# CY8C5568AXI_060 register map
File version: 0.1
Registers are 8-bit, read-write, no defined reset value unless marked. A register's access mark holds for its fields unless they carry their own. Offsets are from the block's base; [hi:lo] are bit positions; {n}, {i} and the like mark numbered series; 'fields as' and 'values as' point back to an identical list.

## IDAC8_PulseIR
Base 0x400043A8
0x00 IDAC8_PM_ACT_CFG — Active Power Mode Configuration Register 8
  [3:0] en_dac — Enable DAC block(s). Populated subsystems are counted from the LSB.
0x10 IDAC8_PM_STBY_CFG — Standby Power Mode Configuration Register 8
  fields as IDAC8_PM_ACT_CFG
0x262 IDAC8_TR
  [7:0] tr — 8 Calibration bits
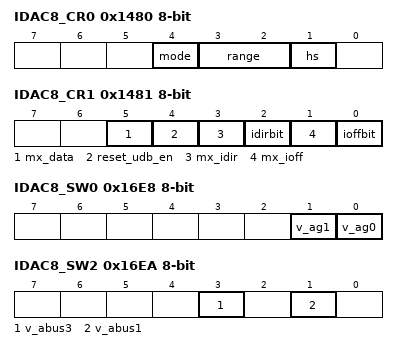
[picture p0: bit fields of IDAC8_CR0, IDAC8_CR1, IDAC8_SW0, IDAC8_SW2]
0x1480 IDAC8_CR0 — DAC Block Control Register 0
  [4] mode ro — Mode Bit
    0=DAC_MODE_V (voltage DAC); 1=DAC_MODE_I (current DAC)
  [3:2] range — Ranges for mode=0 (VDAC) and mode=1 (IDAC)
    0=DAC_RANGE_0 (x0=0V to 4*vref (1.024V); 0 to 31.875uA); 1=DAC_RANGE_1 (x1=0V to 16*vref (4.096V); 0 to 255uA); 2=DAC_RANGE_2 (x0=0V to 4*vref (1.024V); 0 to 2.040mA); 3=DAC_RANGE_3 (x1=0V to 16*vref (4.096V); not used)
  [1] hs — High Speed Bit
    0=DAC_HS_LOWPOWER (regular (low power)); 1=DAC_HS_HIGHSPEED (high speed (higher power))
0x1481 IDAC8_CR1 — DAC Block Control Register 1
  [5] mx_data — Select DATA source
    0=MX_DATA_REG (Select register source); 1=MX_DATA_UDB (Select UDB source)
  [4] reset_udb_en — DAC reset enable
    0=RESET_UDB_EN_DISABLE (Disable DAC Reset Source from UDB); 1=RESET_UDB_EN_ENABLE (Enable DAC Reset Source from UDB)
  [3] mx_idir — Mux selection for DAC current direction control
    0=MX_IDIR_REG (Register source idirbit selected); 1=MX_IDIR_UDB (UDB ictrl selected)
  [2] idirbit — register source for DAC current direction
  [1] mx_ioff — Mux selection for DAC current off control
    0=MX_IOFF_REG (Register source ioffbit selected); 1=MX_IOFF_UDB (UDB ictrl selected)
  [0] ioffbit — register source for DAC current off
0x16E8 IDAC8_SW0 — DAC Analog Routing Register 0
  [1] v_ag1 — Connect voltage output to analog global of same side
    0=AG_NC (not connected); 1=AG_CONNECTED (Connect to Analog Global)
  [0] v_ag0 — Connect voltage output to analog global of same side
    values as v_ag1
0x16EA IDAC8_SW2 — DAC Analog Routing Register 2
  [3] v_abus3 — Connect voltage output to analog (local) bus of the same side
    0=ABUS_NC (not connected); 1=ABUS_CONNECTED (Connect to Analog (local) Bus)
  [1] v_abus1 — Connect voltage output to analog (local) bus of the same side
    values as v_abus3
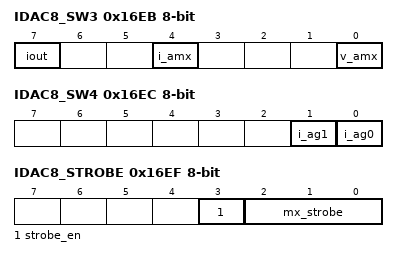
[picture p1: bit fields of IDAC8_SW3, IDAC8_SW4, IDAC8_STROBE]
0x16EB IDAC8_SW3 — DAC Analog Routing Register 3
  [7] iout — Connect current output to pad
    0=IOUT_NC (not connected); 1=IOUT_CONNECT (Connect to pad)
  [4] i_amx — Connect current output to Analog Mux Bus
    0=AMX_NC (not connected); 1=AMX_CONNECTED (Connect to AMUXBUS)
  [0] v_amx — Connect voltage output to Analog Mux Bus
    values as i_amx
0x16EC IDAC8_SW4 — DAC Analog Routing Register 4
  [1] i_ag1 — Connect current output to analog global of same side
    values as IDAC8_SW0.v_ag1
  [0] i_ag0 — Connect current output to analog global of same side
    values as IDAC8_SW0.v_ag1
0x16EF IDAC8_STROBE — DAC Strobe Register
  [3] strobe_en — Strobe gating control
    0=disable strobe; 1=enable strobe
  [2:0] mx_strobe — Strobe source selection
    0=MX_STROBE_BUSWRITE (Select bus write strobe source); 1=MX_STROBE_UDB_SRC (Select UDB strobe source); 2=MX_STROBE_NC_2 (NC); 3=MX_STROBE_NC_3 (NC); {v}=MX_STROBE_CLK_A{v-4}_DIG (Select clk_a{v-4}_dig) (v=4..7)
0x17DA IDAC8_D — DAC Data Register
  [7:0] data — 8 DAC Data bits

## IDAC8_PulseRed
Base 0x400043A8
0x00 IDAC8_PM_ACT_CFG — Active Power Mode Configuration Register 8
  [3:0] en_dac — Enable DAC block(s). Populated subsystems are counted from the LSB.
0x10 IDAC8_PM_STBY_CFG — Standby Power Mode Configuration Register 8
  fields as IDAC8_PM_ACT_CFG
0x260 IDAC8_TR
  [7:0] tr — 8 Calibration bits
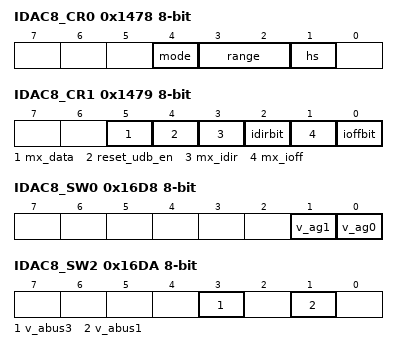
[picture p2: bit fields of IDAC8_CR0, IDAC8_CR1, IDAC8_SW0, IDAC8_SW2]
0x1478 IDAC8_CR0 — DAC Block Control Register 0
  [4] mode ro — Mode Bit
    0=DAC_MODE_V (voltage DAC); 1=DAC_MODE_I (current DAC)
  [3:2] range — Ranges for mode=0 (VDAC) and mode=1 (IDAC)
    0=DAC_RANGE_0 (x0=0V to 4*vref (1.024V); 0 to 31.875uA); 1=DAC_RANGE_1 (x1=0V to 16*vref (4.096V); 0 to 255uA); 2=DAC_RANGE_2 (x0=0V to 4*vref (1.024V); 0 to 2.040mA); 3=DAC_RANGE_3 (x1=0V to 16*vref (4.096V); not used)
  [1] hs — High Speed Bit
    0=DAC_HS_LOWPOWER (regular (low power)); 1=DAC_HS_HIGHSPEED (high speed (higher power))
0x1479 IDAC8_CR1 — DAC Block Control Register 1
  [5] mx_data — Select DATA source
    0=MX_DATA_REG (Select register source); 1=MX_DATA_UDB (Select UDB source)
  [4] reset_udb_en — DAC reset enable
    0=RESET_UDB_EN_DISABLE (Disable DAC Reset Source from UDB); 1=RESET_UDB_EN_ENABLE (Enable DAC Reset Source from UDB)
  [3] mx_idir — Mux selection for DAC current direction control
    0=MX_IDIR_REG (Register source idirbit selected); 1=MX_IDIR_UDB (UDB ictrl selected)
  [2] idirbit — register source for DAC current direction
  [1] mx_ioff — Mux selection for DAC current off control
    0=MX_IOFF_REG (Register source ioffbit selected); 1=MX_IOFF_UDB (UDB ictrl selected)
  [0] ioffbit — register source for DAC current off
0x16D8 IDAC8_SW0 — DAC Analog Routing Register 0
  [1] v_ag1 — Connect voltage output to analog global of same side
    0=AG_NC (not connected); 1=AG_CONNECTED (Connect to Analog Global)
  [0] v_ag0 — Connect voltage output to analog global of same side
    values as v_ag1
0x16DA IDAC8_SW2 — DAC Analog Routing Register 2
  [3] v_abus3 — Connect voltage output to analog (local) bus of the same side
    0=ABUS_NC (not connected); 1=ABUS_CONNECTED (Connect to Analog (local) Bus)
  [1] v_abus1 — Connect voltage output to analog (local) bus of the same side
    values as v_abus3
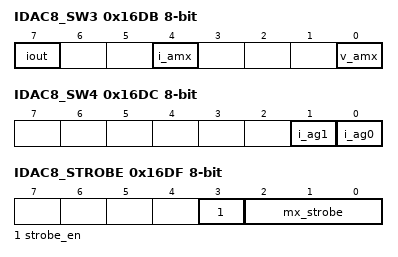
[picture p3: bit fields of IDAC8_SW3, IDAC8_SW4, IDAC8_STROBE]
0x16DB IDAC8_SW3 — DAC Analog Routing Register 3
  [7] iout — Connect current output to pad
    0=IOUT_NC (not connected); 1=IOUT_CONNECT (Connect to pad)
  [4] i_amx — Connect current output to Analog Mux Bus
    0=AMX_NC (not connected); 1=AMX_CONNECTED (Connect to AMUXBUS)
  [0] v_amx — Connect voltage output to Analog Mux Bus
    values as i_amx
0x16DC IDAC8_SW4 — DAC Analog Routing Register 4
  [1] i_ag1 — Connect current output to analog global of same side
    values as IDAC8_SW0.v_ag1
  [0] i_ag0 — Connect current output to analog global of same side
    values as IDAC8_SW0.v_ag1
0x16DF IDAC8_STROBE — DAC Strobe Register
  [3] strobe_en — Strobe gating control
    0=disable strobe; 1=enable strobe
  [2:0] mx_strobe — Strobe source selection
    0=MX_STROBE_BUSWRITE (Select bus write strobe source); 1=MX_STROBE_UDB_SRC (Select UDB strobe source); 2=MX_STROBE_NC_2 (NC); 3=MX_STROBE_NC_3 (NC); {v}=MX_STROBE_CLK_A{v-4}_DIG (Select clk_a{v-4}_dig) (v=4..7)
0x17D8 IDAC8_D — DAC Data Register
  [7:0] data — 8 DAC Data bits

## Opamp_PulseRef
Base 0x400043A4
0x00 PM_ACT_CFG4 — Active Power Mode Configuration Register 4
  [3:0] EN_OPAMP — Enables subsystems during active power mode
    0=Blk_0 (Enables analog linear output buffer for Opamp block 0); 2=Blk_1 (Enables analog linear output buffer for Opamp block 1); 4=Blk_2 (Enables analog linear output buffer for Opamp block 2); 8=Blk_3 (Enables analog linear output buffer for Opamp block 3)
0x10 PM_STBY_CFG4 — Standby Power Mode Configuration Register 4
  [3:0] EN_OPAMP — Enables subsystems during standby power mode
    values as PM_ACT_CFG4.EN_OPAMP
0x27C OPAMP__TR0 — Analog Output Buffer Trim Register 0
  [4:0] offset_trim — Offset Trim: 420uV typical step size; +/- 6.8mV offset trimmable range
0x27D OPAMP__TR1 — Analog Output Buffer Trim Register 1
0x14B4 OPAMP__CR — Analog Output Buffer Configuration Register
  [1:0] pwr_mode — Power Mode
    0=Default_Fast (Default Power mode Fast); 1=Slow (Power Mode Slow); 2=Medium (Power Mode Medium); 3=Fast (Power Mode Fast)
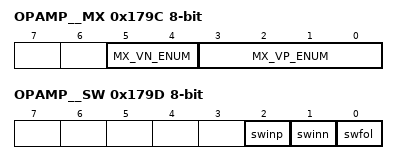
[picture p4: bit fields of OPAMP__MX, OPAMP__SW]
0x179C OPAMP__MX — Analog Buffer Input Selection Register
  [5:4] MX_VN_ENUM — MUX select VN (Negative terminal input)
    0=OPAMP0_MX_VN_DEFAULT (Default - Not Connected (NC)); 1=OPAMP0_MX_VN_AG4 (MUX Selection AGL(4)); 2=OPAMP0_MX_VN_AG6 (MUX Selection AGL(6)); 3=OPAMP0_MX_VN_0x3 (Reserved (NC))
  [3:0] MX_VP_ENUM — MUX select VP (Positive terminal input)
    0=OPAMP0_MX_VP_DEFAULT (Default - Not Connected (NC)); {v}=OPAMP0_MX_VP_AG{v+3} (MUX Selection AGL({v+3})) (v=1..4); {v}=OPAMP0_MX_VP_ABUS{v-5} (MUX Selection ABUSL({v-5})) (v=5..8); 9=OPAMP0_MX_VP_VREF (MUX Selection: OPAMP Voltage Reference); {v}=OPAMP0_MX_VP_H_{0x0+v} (Reserved (NC)) (v=10..15)
0x179D OPAMP__SW — Analog Buffer Routing Switch Register
  [2] swinp — Switch Enable Positive Input
  [1] swinn — Switch Enable Negative Input
  [0] swfol — Switch Enable Follow

## ADC_SAR_ProxIR — SAR ADC
Base 0x40004614
0x00 SAR_TR0 — SAR trim register
{0x12EC+i} SAR_CSR{i} (i=0..6) — SAR status and control register {i}
0x150C SAR_SW0 — SAR Analog Routing Register 0
{0x150C+i} SAR_SW{i} (i=2..4) — SAR Analog Routing Register {i}
0x1512 SAR_SW6 — SAR Analog Routing Register 6
0x1513 SAR_CLK — SAR Clock Selection Register
0x158C SAR_WRK 16-bit — SAR working register
